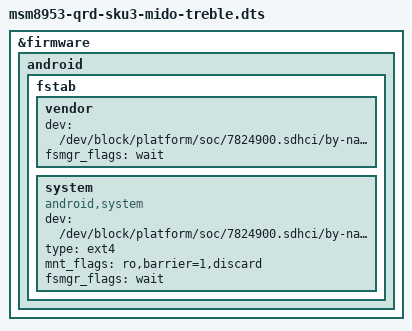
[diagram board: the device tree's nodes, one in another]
/*
 * Copyright (c) 2015-2017, The Linux Foundation. All rights reserved.
 * SPDX-License-Identifier: GPL-2.0-only
 */

/dts-v1/;

#include "msm8953-qrd-sku3-mido-common.dtsi"

&firmware {
	android {
		fstab {
			vendor {
				dev = "/dev/block/platform/soc/7824900.sdhci/by-name/cust";
				fsmgr_flags = "wait";
			};
			system {
				compatible = "android,system";
				dev = "/dev/block/platform/soc/7824900.sdhci/by-name/system";
				type = "ext4";
				mnt_flags = "ro,barrier=1,discard";
				fsmgr_flags = "wait";
				status = "ok";
			};
		};
	};
};
